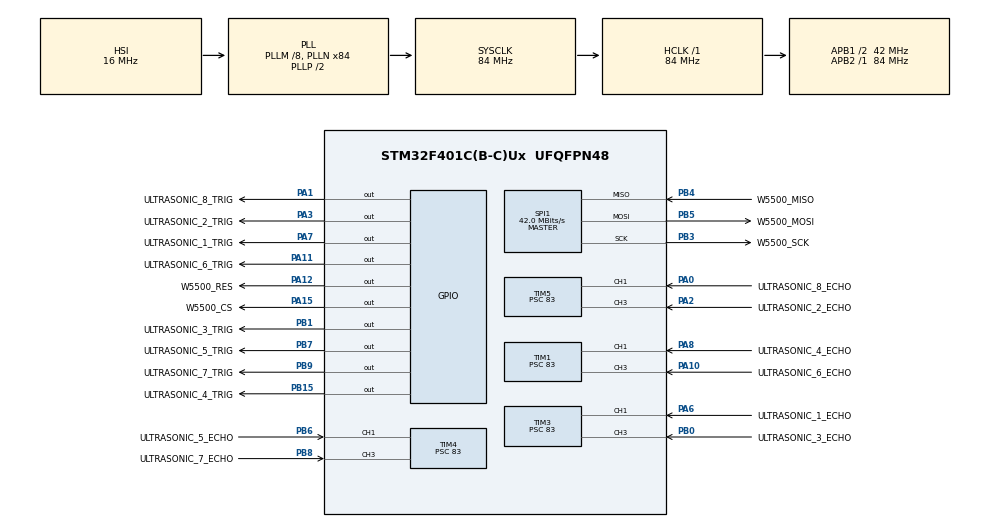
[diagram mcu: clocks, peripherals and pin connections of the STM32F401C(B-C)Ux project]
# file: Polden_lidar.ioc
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Mcu.Family=STM32F4
Mcu.Name=STM32F401C(B-C)Ux
Mcu.Package=UFQFPN48
NVIC.PriorityGroup=NVIC_PRIORITYGROUP_4
NVIC.TIM1_CC_IRQn=true\:0\:0\:false\:false\:true\:true\:true\:true
NVIC.TIM3_IRQn=true\:0\:0\:false\:false\:true\:true\:true\:true
NVIC.TIM4_IRQn=true\:0\:0\:false\:false\:true\:true\:true\:true
NVIC.TIM5_IRQn=true\:0\:0\:false\:false\:true\:true\:true\:true
PA0-WKUP.GPIO_Label=ULTRASONIC_8_ECHO
PA0-WKUP.GPIO_PuPd=GPIO_PULLDOWN
PA0-WKUP.Signal=S_TIM5_CH1
PA1.GPIO_Label=ULTRASONIC_8_TRIG
PA1.Signal=GPIO_Output
PA10.GPIO_Label=ULTRASONIC_6_ECHO
PA10.GPIO_PuPd=GPIO_PULLDOWN
PA10.Signal=S_TIM1_CH3
PA11.GPIO_Label=ULTRASONIC_6_TRIG
PA11.Signal=GPIO_Output
PA12.GPIO_Label=W5500_RES
PA12.Signal=GPIO_Output
PA13.Mode=Serial_Wire
PA13.Signal=SYS_JTMS-SWDIO
PA14.Mode=Serial_Wire
PA14.Signal=SYS_JTCK-SWCLK
PA15.GPIO_Label=W5500_CS
PA15.Signal=GPIO_Output
PA2.GPIO_Label=ULTRASONIC_2_ECHO
PA2.GPIO_PuPd=GPIO_PULLDOWN
PA2.Signal=S_TIM5_CH3
PA3.GPIO_Label=ULTRASONIC_2_TRIG
PA3.Signal=GPIO_Output
PA6.GPIO_Label=ULTRASONIC_1_ECHO
PA6.GPIO_PuPd=GPIO_PULLDOWN
PA6.Signal=S_TIM3_CH1
PA7.GPIO_Label=ULTRASONIC_1_TRIG
PA7.Signal=GPIO_Output
PA8.GPIO_Label=ULTRASONIC_4_ECHO
PA8.GPIO_PuPd=GPIO_PULLDOWN
PA8.Signal=S_TIM1_CH1
PB0.GPIO_Label=ULTRASONIC_3_ECHO
PB0.GPIO_PuPd=GPIO_PULLDOWN
PB0.Signal=S_TIM3_CH3
PB1.GPIO_Label=ULTRASONIC_3_TRIG
PB1.Signal=GPIO_Output
PB15.GPIO_Label=ULTRASONIC_4_TRIG
PB15.Signal=GPIO_Output
PB3.GPIO_Label=W5500_SCK
PB3.Mode=Full_Duplex_Master
PB3.Signal=SPI1_SCK
PB4.GPIO_Label=W5500_MISO
PB4.Mode=Full_Duplex_Master
PB4.Signal=SPI1_MISO
PB5.GPIO_Label=W5500_MOSI
PB5.Mode=Full_Duplex_Master
PB5.Signal=SPI1_MOSI
PB6.GPIO_Label=ULTRASONIC_5_ECHO
PB6.GPIO_PuPd=GPIO_PULLDOWN
PB6.Signal=S_TIM4_CH1
PB7.GPIO_Label=ULTRASONIC_5_TRIG
PB7.Signal=GPIO_Output
PB8.GPIO_Label=ULTRASONIC_7_ECHO
PB8.GPIO_PuPd=GPIO_PULLDOWN
PB8.Signal=S_TIM4_CH3
PB9.GPIO_Label=ULTRASONIC_7_TRIG
PB9.Signal=GPIO_Output
PH0\ -\ OSC_IN.Mode=HSE-External-Oscillator
PH0\ -\ OSC_IN.Signal=RCC_OSC_IN
PH1\ -\ OSC_OUT.Mode=HSE-External-Oscillator
PH1\ -\ OSC_OUT.Signal=RCC_OSC_OUT
ProjectManager.HeapSize=0x200
ProjectManager.StackSize=0x400
ProjectManager.TargetToolchain=STM32CubeIDE
RCC.48MHZClocksFreq_Value=42000000
RCC.AHBFreq_Value=84000000
RCC.APB1CLKDivider=RCC_HCLK_DIV2
RCC.APB1Freq_Value=42000000
RCC.APB1TimFreq_Value=84000000
RCC.APB2Freq_Value=84000000
RCC.APB2TimFreq_Value=84000000
RCC.CortexFreq_Value=84000000
RCC.HCLKFreq_Value=84000000
RCC.HSE_VALUE=25000000
RCC.HSI_VALUE=16000000
RCC.LSE_VALUE=32768
RCC.PLLM=8
RCC.PLLN=84
RCC.SYSCLKFreq_VALUE=84000000
RCC.SYSCLKSource=RCC_SYSCLKSOURCE_PLLCLK
RCC.VCOOutputFreq_Value=168000000
SH.S_TIM1_CH1.0=TIM1_CH1,Input_Capture1_from_TI1
SH.S_TIM1_CH3.0=TIM1_CH3,Input_Capture3_from_TI3
SH.S_TIM3_CH1.0=TIM3_CH1,Input_Capture1_from_TI1
SH.S_TIM3_CH3.0=TIM3_CH3,Input_Capture3_from_TI3
SH.S_TIM4_CH1.0=TIM4_CH1,Input_Capture1_from_TI1
SH.S_TIM4_CH3.0=TIM4_CH3,Input_Capture3_from_TI3
SH.S_TIM5_CH1.0=TIM5_CH1,Input_Capture1_from_TI1
SH.S_TIM5_CH3.0=TIM5_CH3,Input_Capture3_from_TI3
SPI1.CalculateBaudRate=42.0 MBits/s
SPI1.Direction=SPI_DIRECTION_2LINES
SPI1.Mode=SPI_MODE_MASTER
SPI1.VirtualType=VM_MASTER
TIM1.Channel-Input_Capture1_from_TI1=TIM_CHANNEL_1
TIM1.Channel-Input_Capture2_from_TI1_63=TIM_CHANNEL_2
TIM1.Channel-Input_Capture3_from_TI3=TIM_CHANNEL_3
TIM1.Channel-Input_Capture4_from_TI3_63=TIM_CHANNEL_4
TIM1.ICFilter_CH1=15
TIM1.ICFilter_CH3=15
TIM1.ICPolarity_CH2=TIM_INPUTCHANNELPOLARITY_FALLING
TIM1.ICPolarity_CH4=TIM_INPUTCHANNELPOLARITY_FALLING
TIM1.Prescaler=83
TIM2.Prescaler=83
TIM3.Channel-Input_Capture1_from_TI1=TIM_CHANNEL_1
TIM3.Channel-Input_Capture2_from_TI1_63=TIM_CHANNEL_2
TIM3.Channel-Input_Capture3_from_TI3=TIM_CHANNEL_3
TIM3.Channel-Input_Capture4_from_TI3_63=TIM_CHANNEL_4
TIM3.ICFilter_CH1=15
TIM3.ICFilter_CH3=15
TIM3.ICPolarity_CH1=TIM_INPUTCHANNELPOLARITY_RISING
TIM3.ICPolarity_CH2=TIM_INPUTCHANNELPOLARITY_FALLING
TIM3.ICPolarity_CH3=TIM_INPUTCHANNELPOLARITY_RISING
TIM3.ICPolarity_CH4=TIM_INPUTCHANNELPOLARITY_FALLING
TIM3.Prescaler=83
TIM4.Channel-Input_Capture1_from_TI1=TIM_CHANNEL_1
TIM4.Channel-Input_Capture2_from_TI1_63=TIM_CHANNEL_2
TIM4.Channel-Input_Capture3_from_TI3=TIM_CHANNEL_3
TIM4.Channel-Input_Capture4_from_TI3_63=TIM_CHANNEL_4
TIM4.ICFilter_CH1=15
TIM4.ICFilter_CH3=15
TIM4.ICPolarity_CH1=TIM_INPUTCHANNELPOLARITY_RISING
TIM4.ICPolarity_CH2=TIM_INPUTCHANNELPOLARITY_FALLING
TIM4.ICPolarity_CH4=TIM_INPUTCHANNELPOLARITY_FALLING
TIM4.Prescaler=83
TIM5.Channel-Input_Capture1_from_TI1=TIM_CHANNEL_1
TIM5.Channel-Input_Capture2_from_TI1_63=TIM_CHANNEL_2
TIM5.Channel-Input_Capture3_from_TI3=TIM_CHANNEL_3
TIM5.Channel-Input_Capture4_from_TI3_63=TIM_CHANNEL_4
TIM5.ICFilter_CH1=15
TIM5.ICFilter_CH3=15
TIM5.ICPolarity_CH2=TIM_INPUTCHANNELPOLARITY_FALLING
TIM5.ICPolarity_CH4=TIM_INPUTCHANNELPOLARITY_FALLING
TIM5.Period=65535
TIM5.Prescaler=83
VP_TIM1_VS_indirect_ch1.Mode=Input_Capture2_from_TI1_63
VP_TIM1_VS_indirect_ch3.Mode=Input_Capture4_from_TI3_63
VP_TIM2_VS_ClockSourceINT.Mode=Internal
VP_TIM3_VS_indirect_ch1.Mode=Input_Capture2_from_TI1_63
VP_TIM3_VS_indirect_ch3.Mode=Input_Capture4_from_TI3_63
VP_TIM4_VS_indirect_ch1.Mode=Input_Capture2_from_TI1_63
VP_TIM4_VS_indirect_ch3.Mode=Input_Capture4_from_TI3_63
VP_TIM5_VS_indirect_ch1.Mode=Input_Capture2_from_TI1_63
VP_TIM5_VS_indirect_ch3.Mode=Input_Capture4_from_TI3_63
board=custom

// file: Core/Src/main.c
/* USER CODE BEGIN Header */
/**
  ******************************************************************************
  * @file           : main.c
  * @brief          : Main program body
  ******************************************************************************
  * @attention
  *
  * Copyright (c) 2026 STMicroelectronics.
  * All rights reserved.
  *
  * This software is licensed under terms that can be found in the LICENSE file
  * in the root directory of this software component.
  * If no LICENSE file comes with this software, it is provided AS-IS.
  *
  ******************************************************************************
  */
/* USER CODE END Header */
#include "main.h"
#include "spi.h"
#include "tim.h"
#include "gpio.h"

/* USER CODE BEGIN Includes */
#include "Polden_lidar_main.h"
/* USER CODE END Includes */

void SystemClock_Config(void);

int main(void)
{

  /* MCU Configuration--------------------------------------------------------*/

  /* Reset of all peripherals, Initializes the Flash interface and the Systick. */
  HAL_Init();

  /* Configure the system clock */
  SystemClock_Config();

  /* Initialize all configured peripherals */
  MX_GPIO_Init();
  MX_SPI1_Init();
  MX_TIM1_Init();
  MX_TIM2_Init();
  MX_TIM3_Init();
  MX_TIM4_Init();
  MX_TIM5_Init();
  /* USER CODE BEGIN 2 */

  polden_lidar_main();

  /* USER CODE END 2 */

  /* Infinite loop */
  while (1)
  {

  }
}

void SystemClock_Config(void)
{
  RCC_OscInitTypeDef RCC_OscInitStruct = {0};
  RCC_ClkInitTypeDef RCC_ClkInitStruct = {0};

  /** Configure the main internal regulator output voltage
  */
  __HAL_RCC_PWR_CLK_ENABLE();
  __HAL_PWR_VOLTAGESCALING_CONFIG(PWR_REGULATOR_VOLTAGE_SCALE2);

  /** Initializes the RCC Oscillators according to the specified parameters
  * in the RCC_OscInitTypeDef structure.
  */
  RCC_OscInitStruct.OscillatorType = RCC_OSCILLATORTYPE_HSI|RCC_OSCILLATORTYPE_LSI;
  RCC_OscInitStruct.HSIState = RCC_HSI_ON;
  RCC_OscInitStruct.HSICalibrationValue = RCC_HSICALIBRATION_DEFAULT;
  RCC_OscInitStruct.LSIState = RCC_LSI_ON;
  RCC_OscInitStruct.PLL.PLLState = RCC_PLL_ON;
  RCC_OscInitStruct.PLL.PLLSource = RCC_PLLSOURCE_HSI;
  RCC_OscInitStruct.PLL.PLLM = 8;
  RCC_OscInitStruct.PLL.PLLN = 84;
  RCC_OscInitStruct.PLL.PLLP = RCC_PLLP_DIV2;
  RCC_OscInitStruct.PLL.PLLQ = 4;
  if (HAL_RCC_OscConfig(&RCC_OscInitStruct) != HAL_OK)
  {
    Error_Handler();
  }

  /** Initializes the CPU, AHB and APB buses clocks
  */
  RCC_ClkInitStruct.ClockType = RCC_CLOCKTYPE_HCLK|RCC_CLOCKTYPE_SYSCLK
                              |RCC_CLOCKTYPE_PCLK1|RCC_CLOCKTYPE_PCLK2;
  RCC_ClkInitStruct.SYSCLKSource = RCC_SYSCLKSOURCE_PLLCLK;
  RCC_ClkInitStruct.AHBCLKDivider = RCC_SYSCLK_DIV1;
  RCC_ClkInitStruct.APB1CLKDivider = RCC_HCLK_DIV2;
  RCC_ClkInitStruct.APB2CLKDivider = RCC_HCLK_DIV1;

  if (HAL_RCC_ClockConfig(&RCC_ClkInitStruct, FLASH_LATENCY_2) != HAL_OK)
  {
    Error_Handler();
  }
}

void Error_Handler(void)
{
  __disable_irq();
  while (1)
  {
  }
}
